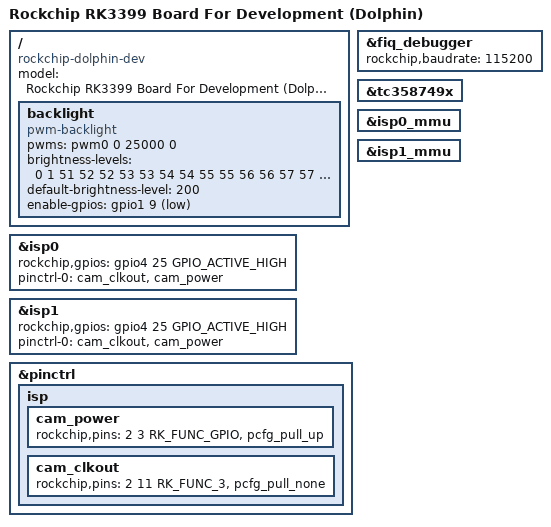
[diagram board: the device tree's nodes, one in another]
/*
 * Copyright (c) 2016 Fuzhou Rockchip Electronics Co., Ltd
 *
 * This file is dual-licensed: you can use it either under the terms
 * of the GPL or the X11 license, at your option. Note that this dual
 * licensing only applies to this file, and not this project as a
 * whole.
 *
 *  a) This file is free software; you can redistribute it and/or
 *     modify it under the terms of the GNU General Public License as
 *     published by the Free Software Foundation; either version 2 of the
 *     License, or (at your option) any later version.
 *
 *     This file is distributed in the hope that it will be useful,
 *     but WITHOUT ANY WARRANTY; without even the implied warranty of
 *     MERCHANTABILITY or FITNESS FOR A PARTICULAR PURPOSE.  See the
 *     GNU General Public License for more details.
 *
 * Or, alternatively,
 *
 *  b) Permission is hereby granted, free of charge, to any person
 *     obtaining a copy of this software and associated documentation
 *     files (the "Software"), to deal in the Software without
 *     restriction, including without limitation the rights to use,
 *     copy, modify, merge, publish, distribute, sublicense, and/or
 *     sell copies of the Software, and to permit persons to whom the
 *     Software is furnished to do so, subject to the following
 *     conditions:
 *
 *     The above copyright notice and this permission notice shall be
 *     included in all copies or substantial portions of the Software.
 *
 *     THE SOFTWARE IS PROVIDED "AS IS", WITHOUT WARRANTY OF ANY KIND,
 *     EXPRESS OR IMPLIED, INCLUDING BUT NOT LIMITED TO THE WARRANTIES
 *     OF MERCHANTABILITY, FITNESS FOR A PARTICULAR PURPOSE AND
 *     NONINFRINGEMENT. IN NO EVENT SHALL THE AUTHORS OR COPYRIGHT
 *     HOLDERS BE LIABLE FOR ANY CLAIM, DAMAGES OR OTHER LIABILITY,
 *     WHETHER IN AN ACTION OF CONTRACT, TORT OR OTHERWISE, ARISING
 *     FROM, OUT OF OR IN CONNECTION WITH THE SOFTWARE OR THE USE OR
 *     OTHER DEALINGS IN THE SOFTWARE.
 */

/dts-v1/;
#include "rk3399-dolphin.dtsi"
#include <dt-bindings/display/screen-timing/panel-toshiba-tc358775.dtsi>

/ {
	model = "Rockchip RK3399 Board For Development (Dolphin)";
	compatible = "rockchip-dolphin-dev","rockchip,rk3399-dolphin";

	backlight: backlight {
		compatible = "pwm-backlight";
		pwms = <&pwm0 0 25000 0>;
		brightness-levels = <
			0   1   51  52  52  53  53  54
			54  55  55  56  56  57  57  58
			58  59  59  60  61  61  62  63
			63  64  65  65  66  67  67  68
			69  69  70  71  71  72  73  73
			74  75  75  76  77  77  78  79
			79  80  80  81  81  82  83  83
			84  85  86  86  87  88  89  89
			90  91  92  92  93  94  95  95
			96  97  98  98  99 100 101  101
			102 103 104 104 105 106 107 107
			108 109 110 110 111 112 113 113
			114 115 116 116 117 118 119 119
			120 121 122 122 123 124 125 125
			126 127 128 128 129 130 131 131
			132 133 134 134 135 136 137 137
			138 139 140 140 141 142 143 143
			144 145 146 146 147 148 149 149
			150 151 152 152 153 154 155 155
			156 157 158 158 159 160 161 161
			162 163 164 164 165 166 167 167
			168 169 170 170 171 172 173 173
			174 175 176 176 177 178 179 179
			180 181 182 182 183 184 185 185
			186 187 188 188 189 190 191 191
			216 217 218 218 219 220 221 221
			222 223 224 224 225 226 227 227
			228 229 230 230 231 232 233 233
			234 235 236 236 237 238 239 239
			240 241 242 242 243 244 245 245
			246 247 248 248 249 250 251 251
			252 253 254 254 255 255 255 255>;
		default-brightness-level = <200>;
		enable-gpios = <&gpio1 9 GPIO_ACTIVE_LOW>;
	};
};

&fiq_debugger {
	rockchip,baudrate = <115200>;
};

&tc358749x {
	status = "okay";
};

&isp0 {
	status = "okay";
	// Unused gpio: gpio4_d1
	rockchip,gpios = <&gpio4 25 GPIO_ACTIVE_HIGH>;
	pinctrl-names = "default";
	pinctrl-0 = <&cam_clkout &cam_power>;
};

&isp0_mmu {
	status = "okay";
};

&isp1 {
	status = "okay";
	// Unused gpio: gpio4_d1
	rockchip,gpios = <&gpio4 25 GPIO_ACTIVE_HIGH>;
	pinctrl-names = "default";
	pinctrl-0 = <&cam_clkout &cam_power>;
};

&isp1_mmu {
	status = "okay";
};

&pinctrl {
	isp {
		cam_power: cam_power {
			rockchip,pins = <2 3 RK_FUNC_GPIO &pcfg_pull_up>;
		};

		cam_clkout: cam_clkout {
			rockchip,pins = <2 11 RK_FUNC_3 &pcfg_pull_none>;
		};
	};
};
